# WLR089U0 register map
Vendor: Microchip
Registers are 32-bit, read-write, reset 0x0 unless marked. A register's access mark holds for its fields unless they carry their own. Addresses are absolute, and some are shared; only a register's first bit layout is shown; [hi:lo] are bit positions; {n}, {i} and the like mark numbered series; 'fields as' and 'values as' point back to an identical list.

## DMAC
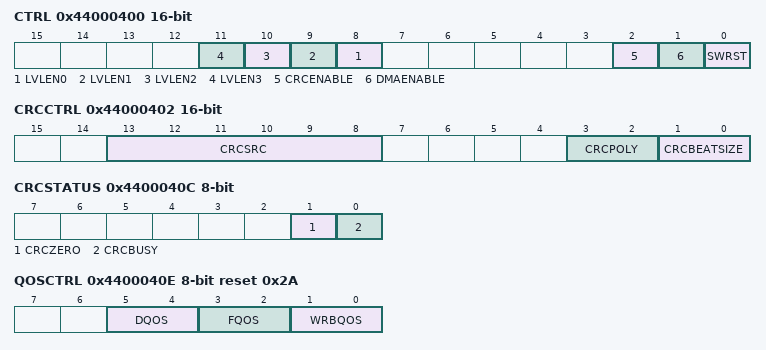
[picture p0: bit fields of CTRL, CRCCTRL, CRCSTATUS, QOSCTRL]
0x44000400 CTRL 16-bit
  [n+8] LVLEN{n} (n=0..3) — Priority Level {n} Enable
  [2] CRCENABLE
  [1] DMAENABLE
  [0] SWRST — Software Reset
0x44000402 CRCCTRL 16-bit
  [13:8] CRCSRC — CRC Input Source
    0=NOACT (No action); 1=IO (I/O interface)
  [3:2] CRCPOLY — CRC Polynomial Type
    0=CRC16 (CRC-16 (CRC-CCITT)); 1=CRC32 (CRC32 (IEEE 802.3))
  [1:0] CRCBEATSIZE
    0=BYTE (8-bit bus transfer); 1=HWORD (16-bit bus transfer); 2=WORD (32-bit bus transfer)
0x44000404 CRCDATAIN
  [31:0] CRCDATAIN — CRC Data Input
0x44000408 CRCCHKSUM
  [31:0] CRCCHKSUM — CRC Checksum
0x4400040C CRCSTATUS 8-bit
  [1] CRCZERO
  [0] CRCBUSY — CRC Module Busy
0x4400040D DBGCTRL 8-bit
  [0] DBGRUN — Debug Run
0x4400040E QOSCTRL 8-bit reset 0x2A
  [all] fields
    0=DISABLE (Background (no sensitive operation)); 1=LOW (Sensitive Bandwidth); 2=MEDIUM (Sensitive Latency); 3=HIGH (Critical Latency)
  [5:4] DQOS — Data Transfer Quality of Service
  [3:2] FQOS — Fetch Quality of Service
  [1:0] WRBQOS — Write-Back Quality of Service
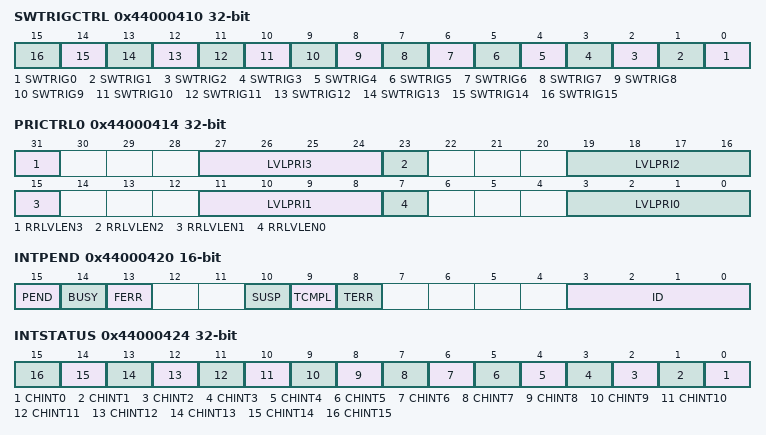
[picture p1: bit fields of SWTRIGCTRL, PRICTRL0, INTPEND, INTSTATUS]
0x44000410 SWTRIGCTRL
  [n] SWTRIG{n} (n=0..15) — Channel {n} Software Trigger
0x44000414 PRICTRL0
  [31] RRLVLEN3 — Level 3 Round-Robin Scheduling Enable
  [8n+3:8n] LVLPRI{n} (n=0..3) — Level {n} Channel Priority Number
  [23] RRLVLEN2 — Level 2 Round-Robin Scheduling Enable
  [15] RRLVLEN1 — Level 1 Round-Robin Scheduling Enable
  [7] RRLVLEN0 — Level 0 Round-Robin Scheduling Enable
    0=STATIC_LVL (Static arbitration scheme for channels with level 3 priority); 1=ROUND_ROBIN_LVL (Round-robin arbitration scheme for channels with level 3 priority)
0x44000420 INTPEND 16-bit
  [15] PEND — Pending
  [14] BUSY
  [13] FERR — Fetch Error
  [10] SUSP — Channel Suspend
  [9] TCMPL — Transfer Complete
  [8] TERR — Transfer Error
  [3:0] ID — Channel ID
0x44000424 INTSTATUS ro
  [n] CHINT{n} (n=0..15) — Channel {n} Pending Interrupt
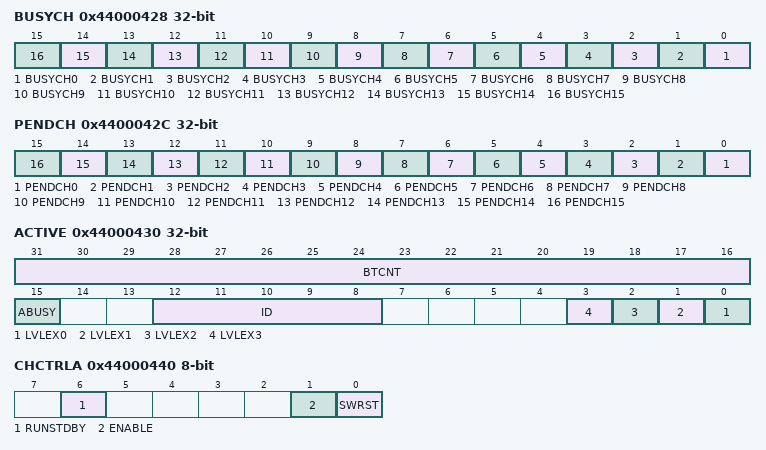
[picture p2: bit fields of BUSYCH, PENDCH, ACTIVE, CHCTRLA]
0x44000428 BUSYCH ro
  [n] BUSYCH{n} (n=0..15) — Busy Channel {n}
0x4400042C PENDCH ro
  [n] PENDCH{n} (n=0..15) — Pending Channel {n}
0x44000430 ACTIVE ro
  [31:16] BTCNT — Active Channel Block Transfer Count
  [15] ABUSY — Active Channel Busy
  [12:8] ID — Active Channel ID
  [n] LVLEX{n} (n=0..3) — Level {n} Channel Trigger Request Executing
0x44000434 BASEADDR
  [31:0] BASEADDR — Descriptor Memory Base Address
0x44000438 WRBADDR
  [31:0] WRBADDR — Write-Back Memory Base Address
0x4400043F CHID 8-bit
  [3:0] ID — Channel ID
0x44000440 CHCTRLA 8-bit
  [6] RUNSTDBY — Channel run in standby
  [1] ENABLE — Channel Enable
  [0] SWRST — Channel Software Reset
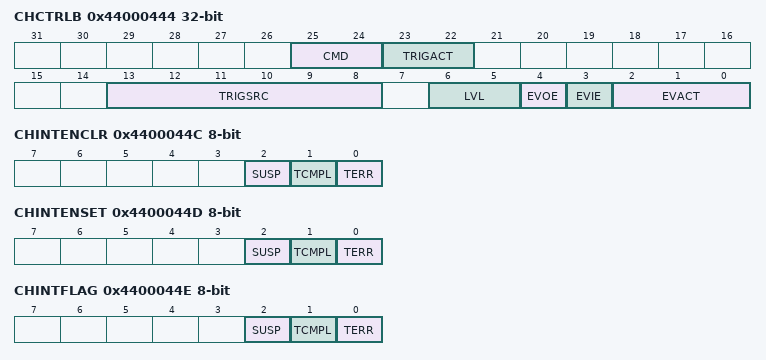
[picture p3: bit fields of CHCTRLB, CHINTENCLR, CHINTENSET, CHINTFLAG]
0x44000444 CHCTRLB
  [25:24] CMD — Software Command
    0=NOACT (No action); 1=SUSPEND (Channel suspend operation); 2=RESUME (Channel resume operation)
  [23:22] TRIGACT — Trigger Action
    0=BLOCK (One trigger required for each block transfer); 2=BEAT (One trigger required for each beat transfer); 3=TRANSACTION (One trigger required for each transaction)
  [13:8] TRIGSRC — Trigger Source
    0=DISABLE (Only software/event triggers)
  [6:5] LVL — Channel Arbitration Level
    {v}=Channel Priority Level {v} (v=0..3)
  [4] EVOE — Channel Event Output Enable
  [3] EVIE — Channel Event Input Enable
  [2:0] EVACT — Event Input Action
    0=NOACT (No action); 1=TRIG (Transfer and periodic transfer trigger); 2=CTRIG (Conditional transfer trigger); 3=CBLOCK (Conditional block transfer); 4=SUSPEND (Channel suspend operation); 5=RESUME (Channel resume operation); 6=SSKIP (Skip next block suspend action)
0x4400044C CHINTENCLR 8-bit
  [2] SUSP — Channel Suspend Interrupt Enable
  [1] TCMPL — Channel Transfer Complete Interrupt Enable
  [0] TERR — Channel Transfer Error Interrupt Enable
0x4400044D CHINTENSET 8-bit
  fields as CHINTENCLR
0x4400044E CHINTFLAG 8-bit
  [2] SUSP — Channel Suspend
  [1] TCMPL — Channel Transfer Complete
  [0] TERR — Channel Transfer Error
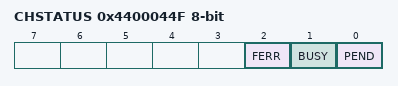
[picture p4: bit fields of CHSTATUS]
0x4400044F CHSTATUS 8-bit ro
  [2] FERR — Channel Fetch Error
  [1] BUSY — Channel Busy
  [0] PEND — Channel Pending
